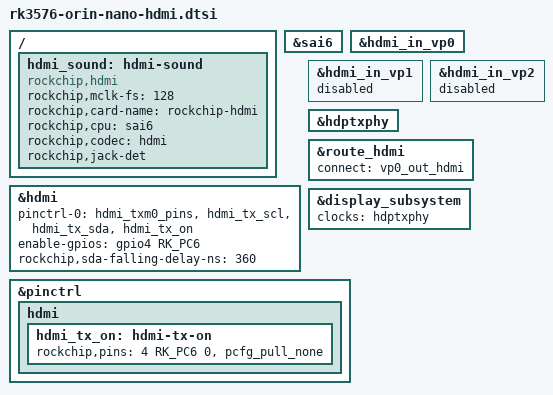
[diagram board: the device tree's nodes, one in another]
// SPDX-License-Identifier: (GPL-2.0+ OR MIT)
/*
 * Guangzhou Easy EAI Technology Co., Ltd.
 *
 */

/ {
	hdmi_sound: hdmi-sound {
		compatible = "rockchip,hdmi";
		rockchip,mclk-fs = <128>;
		rockchip,card-name = "rockchip-hdmi";
		rockchip,cpu = <&sai6>;
		rockchip,codec = <&hdmi>;
		rockchip,jack-det;
	};
};

&sai6 {
	status = "okay";
};

&hdmi {
	pinctrl-names = "default";
	pinctrl-0 = <&hdmi_txm0_pins &hdmi_tx_scl &hdmi_tx_sda &hdmi_tx_on>;
	status = "okay";
	enable-gpios = <&gpio4 RK_PC6 GPIO_ACTIVE_HIGH>;
	rockchip,sda-falling-delay-ns = <360>;
};

&hdmi_in_vp0 {
	status = "okay";
};

&hdmi_in_vp1 {
	status = "disabled";
};

&hdmi_in_vp2 {
	status = "disabled";
};

&hdptxphy {
	status = "okay";
};

&route_hdmi {
	status = "okay";
	connect = <&vp0_out_hdmi>;
};

&display_subsystem {
	clocks = <&hdptxphy>;
	clock-names = "hdmi0_phy_pll";
};


&pinctrl {
	hdmi {
		/omit-if-no-ref/
		hdmi_tx_on: hdmi-tx-on {
			rockchip,pins = <4 RK_PC6 0 &pcfg_pull_none>;
		};
	};
};

